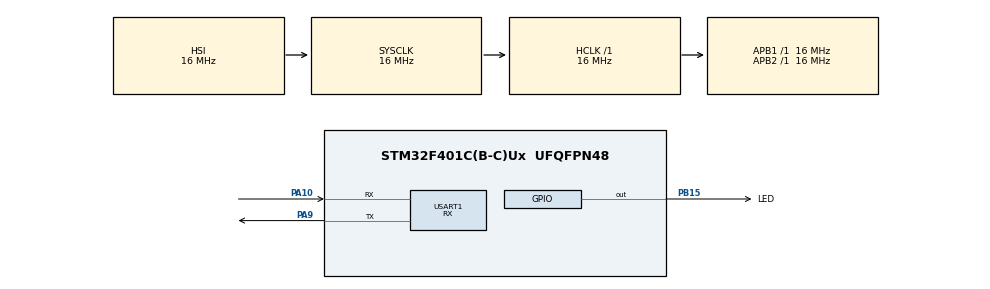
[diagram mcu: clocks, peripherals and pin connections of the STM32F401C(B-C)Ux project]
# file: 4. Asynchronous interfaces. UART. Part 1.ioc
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Mcu.Family=STM32F4
Mcu.Name=STM32F401C(B-C)Ux
Mcu.Package=UFQFPN48
NVIC.PriorityGroup=NVIC_PRIORITYGROUP_4
NVIC.USART1_IRQn=true\:0\:0\:false\:false\:true\:true\:true\:true
PA10.Mode=Asynchronous
PA10.Signal=USART1_RX
PA13.Mode=Serial_Wire
PA13.Signal=SYS_JTMS-SWDIO
PA14.Mode=Serial_Wire
PA14.Signal=SYS_JTCK-SWCLK
PA9.Mode=Asynchronous
PA9.Signal=USART1_TX
PB15.GPIO_Label=LED
PB15.PinState=GPIO_PIN_SET
PB15.Signal=GPIO_Output
ProjectManager.HeapSize=0x200
ProjectManager.StackSize=0x400
ProjectManager.TargetToolchain=STM32CubeIDE
RCC.AHBFreq_Value=16000000
RCC.APB1Freq_Value=16000000
RCC.APB2Freq_Value=16000000
RCC.CortexFreq_Value=16000000
RCC.HSE_VALUE=25000000
RCC.HSI_VALUE=16000000
RCC.LSE_VALUE=32768
RCC.SYSCLKFreq_VALUE=16000000
RCC.VCOOutputFreq_Value=192000000
USART1.Mode=MODE_RX
USART1.VirtualMode=VM_ASYNC
board=custom

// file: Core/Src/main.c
/* USER CODE BEGIN Header */
/**
  ******************************************************************************
  * @file           : main.c
  * @brief          : Main program body
  ******************************************************************************
  * @attention
  *
  * Copyright (c) 2024 STMicroelectronics.
  * All rights reserved.
  *
  * This software is licensed under terms that can be found in the LICENSE file
  * in the root directory of this software component.
  * If no LICENSE file comes with this software, it is provided AS-IS.
  *
  ******************************************************************************
  */
/* USER CODE END Header */
#include "main.h"
#include "usart.h"
#include "gpio.h"

/* USER CODE BEGIN Includes */

#include "comand.h"

/* USER CODE END Includes */

/* USER CODE BEGIN PD */

#define RX_TEXT_LEN 30
#define TX_TEXT_LEN 30

#define RX_LEN 1
#define TX_LEN 1

#define IDLE1

/* USER CODE END PD */

/* USER CODE BEGIN PV */

volatile uint8_t RxBuffer[RX_TEXT_LEN * sizeof(uint8_t)] = {0};
volatile uint8_t TxBuffer[TX_LEN * sizeof(uint8_t)] = {0};

volatile uint8_t UART1_RxCplt = 0;

/* USER CODE END PV */

void SystemClock_Config(void);
/* USER CODE BEGIN PFP */

void clear_cplt_res(uint8_t *flag, uint8_t buffer[]);

/* USER CODE END PFP */

int main(void)
{

  /* MCU Configuration--------------------------------------------------------*/

  /* Reset of all peripherals, Initializes the Flash interface and the Systick. */
  HAL_Init();

  /* Configure the system clock */
  SystemClock_Config();

  /* Initialize all configured peripherals */
  MX_GPIO_Init();
  MX_USART1_UART_Init();
  /* USER CODE BEGIN 2 */

  //UART1_Transmit_IT(TxBuffer, RX_TEXT_LEN);

#ifndef IDLE

  HAL_UART_Receive_IT(&huart1, RxBuffer, RX_LEN);

#else

  HAL_UARTEx_ReceiveToIdle_IT(&huart1, RxBuffer, RX_TEXT_LEN);

#endif
  /* USER CODE END 2 */

  /* Infinite loop */
  /* USER CODE BEGIN WHILE */
  while (1)
  {
	if(UART1_RxCplt){

#ifndef IDLE

		comand_out_t comand = (comand_out_t)(RxBuffer[0] - '0');
		execute_comand(comand);

		clear_cplt_res(&UART1_RxCplt, RxBuffer);
		HAL_UART_Receive_IT(&huart1, RxBuffer, RX_LEN);

#else
		comand_out_t comand = parse_text_comand(RxBuffer, RX_TEXT_LEN);
		execute_comand(comand);

		clear_cplt_res(&UART1_RxCplt, RxBuffer);
		HAL_UARTEx_ReceiveToIdle_IT(&huart1, RxBuffer, RX_TEXT_LEN);

#endif

	}
    /* USER CODE END WHILE */

    /* USER CODE BEGIN 3 */
  }
  return 0;
  /* USER CODE END 3 */
}

void SystemClock_Config(void)
{
  RCC_OscInitTypeDef RCC_OscInitStruct = {0};
  RCC_ClkInitTypeDef RCC_ClkInitStruct = {0};

  /** Configure the main internal regulator output voltage
  */
  __HAL_RCC_PWR_CLK_ENABLE();
  __HAL_PWR_VOLTAGESCALING_CONFIG(PWR_REGULATOR_VOLTAGE_SCALE2);

  /** Initializes the RCC Oscillators according to the specified parameters
  * in the RCC_OscInitTypeDef structure.
  */
  RCC_OscInitStruct.OscillatorType = RCC_OSCILLATORTYPE_HSI;
  RCC_OscInitStruct.HSIState = RCC_HSI_ON;
  RCC_OscInitStruct.HSICalibrationValue = RCC_HSICALIBRATION_DEFAULT;
  RCC_OscInitStruct.PLL.PLLState = RCC_PLL_NONE;
  if (HAL_RCC_OscConfig(&RCC_OscInitStruct) != HAL_OK)
  {
    Error_Handler();
  }

  /** Initializes the CPU, AHB and APB buses clocks
  */
  RCC_ClkInitStruct.ClockType = RCC_CLOCKTYPE_HCLK|RCC_CLOCKTYPE_SYSCLK
                              |RCC_CLOCKTYPE_PCLK1|RCC_CLOCKTYPE_PCLK2;
  RCC_ClkInitStruct.SYSCLKSource = RCC_SYSCLKSOURCE_HSI;
  RCC_ClkInitStruct.AHBCLKDivider = RCC_SYSCLK_DIV1;
  RCC_ClkInitStruct.APB1CLKDivider = RCC_HCLK_DIV1;
  RCC_ClkInitStruct.APB2CLKDivider = RCC_HCLK_DIV1;

  if (HAL_RCC_ClockConfig(&RCC_ClkInitStruct, FLASH_LATENCY_0) != HAL_OK)
  {
    Error_Handler();
  }
}

/* USER CODE BEGIN 4 */

#ifndef IDLE

void HAL_UART_RxCpltCallback(UART_HandleTypeDef *huart){

	if (huart == &huart1){

		UART1_RxCplt = 1;
	}

}

#else

void HAL_UARTEx_RxEventCallback(UART_HandleTypeDef *huart, uint16_t Size)
{
	if (huart == &huart1){

		UART1_RxCplt = 1;
	}
}

#endif

void clear_cplt_res(uint8_t *flag, uint8_t buffer[])
{
	buffer[0] = '\0';
	*flag = 0;
}

/* USER CODE END 4 */

void Error_Handler(void)
{
  __disable_irq();
  while (1)
  {
  }
}
